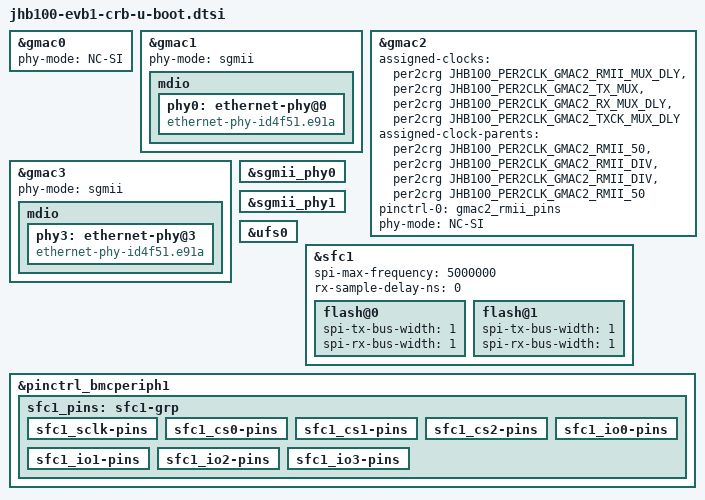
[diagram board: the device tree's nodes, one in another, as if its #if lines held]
// SPDX-License-Identifier: GPL-2.0 OR MIT
/*
 * Copyright (c) 2021-2022 StarFive Technology Co., Ltd.
 */

#include "jhb100-u-boot.dtsi"
#include "jhb100-evb1-sfc1-flash.dtsi"

&gmac0 {
	bootph-pre-ram;
	/delete-property/ assigned-clock-parents;
	/delete-property/ assigned-clocks;

#ifdef CONFIG_PHY_NCSI
	phy-mode = "NC-SI";
#else
	mdio {
		bootph-pre-ram;
		phy1: ethernet-phy@1 {
			compatible = "ethernet-phy-id4f51.e928";
			bootph-pre-ram;
		};
	};
#endif
};

&gmac1 {
	bootph-pre-ram;
	phy-mode = "sgmii";

	mdio {
		bootph-pre-ram;
		phy0: ethernet-phy@0 {
			compatible = "ethernet-phy-id4f51.e91a";
			bootph-pre-ram;
		};
	};
};

&gmac2 {
	bootph-pre-ram;
	/delete-property/ assigned-clock-parents;

#ifdef CONFIG_PHY_NCSI
	assigned-clocks = <&per2crg JHB100_PER2CLK_GMAC2_RMII_MUX_DLY>,
			  <&per2crg JHB100_PER2CLK_GMAC2_TX_MUX>,
			  <&per2crg JHB100_PER2CLK_GMAC2_RX_MUX_DLY>,
			  <&per2crg JHB100_PER2CLK_GMAC2_TXCK_MUX_DLY>;
	assigned-clock-parents = <&per2crg JHB100_PER2CLK_GMAC2_RMII_50>,
				 <&per2crg JHB100_PER2CLK_GMAC2_RMII_DIV>,
				 <&per2crg JHB100_PER2CLK_GMAC2_RMII_DIV>,
				 <&per2crg JHB100_PER2CLK_GMAC2_RMII_50>;
	pinctrl-names = "default";
	pinctrl-0 = <&gmac2_rmii_pins>;
	phy-mode = "NC-SI";
#else
	assigned-clocks = <&per2crg JHB100_PER2CLK_GMAC2_RX_MUX_DLY>,
			  <&per2crg JHB100_PER2CLK_GMAC2_TX_MUX>,
			  <&per2crg JHB100_PER2CLK_GMAC2_TXCK_MUX_DLY>;
	assigned-clock-parents = <&per2crg JHB100_PER2CLK_GMAC2_RGMII_125_MUX>,
				 <&per2crg JHB100_PER2CLK_GMAC2_RGMII_DIV>,
				 <&per2crg JHB100_PER2CLK_GMAC2_TX_MUX>;
	mdio {
		bootph-pre-ram;
		phy2: ethernet-phy@2 {
			compatible = "ethernet-phy-id4f51.e91b";
			bootph-pre-ram;
		};
	};
#endif
};

&gmac3 {
	bootph-pre-ram;
	phy-mode = "sgmii";

	mdio {
		bootph-pre-ram;
		phy3: ethernet-phy@3 {
			compatible = "ethernet-phy-id4f51.e91a";
			bootph-pre-ram;
		};
	};
};

&sgmii_phy0 {
	bootph-pre-ram;
};

&sgmii_phy1 {
	bootph-pre-ram;
};

&ufs0 {
	bootph-pre-ram;
	status = "okay";
};

&sfc1 {
	bootph-pre-ram;
	spi-max-frequency = <5000000>;
	rx-sample-delay-ns = <0>;
	/delete-property/ resets;
	/delete-property/ dmas;

	flash@0 {
		spi-tx-bus-width = <1>;
		spi-rx-bus-width = <1>;
	};

	flash@1 {
		spi-tx-bus-width = <1>;
		spi-rx-bus-width = <1>;
	};
};

&pinctrl_bmcperiph1 {
	bootph-pre-ram;

	sfc1_pins: sfc1-grp {
		bootph-pre-ram;

		sfc1_sclk-pins {
			bootph-pre-ram;
		};

		sfc1_cs0-pins {
			bootph-pre-ram;
		};

		sfc1_cs1-pins {
			bootph-pre-ram;
		};

		sfc1_cs2-pins {
			bootph-pre-ram;
		};

		sfc1_io0-pins {
			bootph-pre-ram;
		};

		sfc1_io1-pins {
			bootph-pre-ram;
		};

		sfc1_io2-pins {
			bootph-pre-ram;
		};

		sfc1_io3-pins {
			bootph-pre-ram;
		};
	};
};
